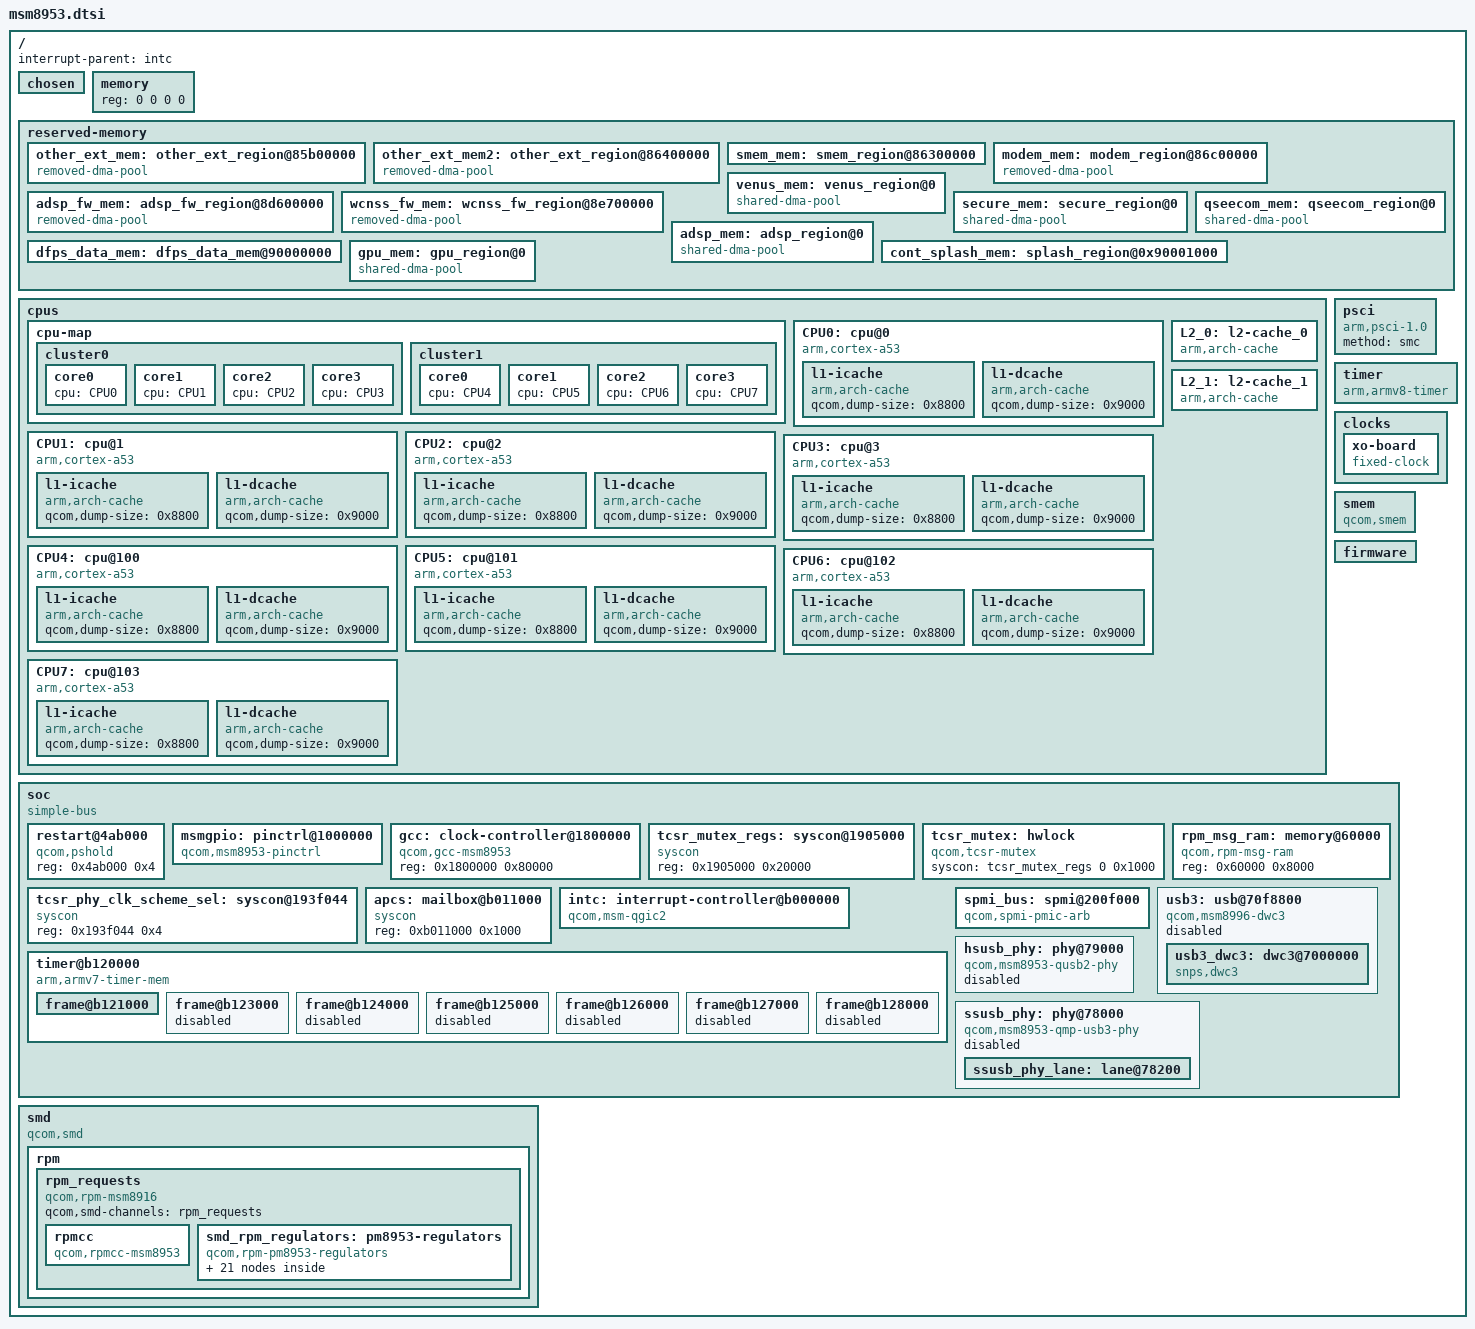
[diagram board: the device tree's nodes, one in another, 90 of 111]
// SPDX-License-Identifier: GPL-2.0-only
/* Copyright (c) 2020, The Linux Foundation. All rights reserved.
 */
#include <dt-bindings/interrupt-controller/arm-gic.h>
#include <dt-bindings/clock/qcom,gcc-msm8953.h>
#include <dt-bindings/clock/qcom,rpmcc.h>

/ {
	interrupt-parent = <&intc>;
	#address-cells = <2>;
	#size-cells = <2>;

	chosen { };

	memory {
		device_type = "memory";
		/* We expect the bootloader to fill in the reg */
		reg = <0 0 0 0>;
	};

	reserved-memory {
		#address-cells = <2>;
		#size-cells = <2>;
		ranges;

		other_ext_mem: other_ext_region@85b00000 {
			compatible = "removed-dma-pool";
			no-map;
			reg = <0x0 0x85b00000 0x0 0x800000>;
		};

		other_ext_mem2: other_ext_region@86400000 {
			compatible = "removed-dma-pool";
			no-map;
			reg = <0x0 0x86400000 0x0 0x400000>;
		};

		smem_mem: smem_region@86300000 {
			reg = <0x0 0x86300000 0x0 0x100000>;
			no-map;
		};

		modem_mem: modem_region@86c00000 {
			compatible = "removed-dma-pool";
			no-map-fixup;
			reg = <0x0 0x86c00000 0x0 0x6a00000>;
		};

		adsp_fw_mem: adsp_fw_region@8d600000 {
			compatible = "removed-dma-pool";
			no-map;
			reg = <0x0 0x8d600000 0x0 0x1100000>;
		};

		wcnss_fw_mem: wcnss_fw_region@8e700000 {
			compatible = "removed-dma-pool";
			no-map;
			reg = <0x0 0x8e700000 0x0 0x700000>;
		};

		venus_mem: venus_region@0 {
			compatible = "shared-dma-pool";
			reusable;
			alloc-ranges = <0x0 0x80000000 0x0 0x10000000>;
			alignment = <0 0x400000>;
			size = <0 0x0800000>;
		};

		secure_mem: secure_region@0 {
			compatible = "shared-dma-pool";
			reusable;
			alignment = <0 0x400000>;
			size = <0 0x09800000>;
		};

		qseecom_mem: qseecom_region@0 {
			compatible = "shared-dma-pool";
			reusable;
			alignment = <0 0x400000>;
			size = <0 0x1000000>;
		};

		adsp_mem: adsp_region@0 {
			compatible = "shared-dma-pool";
			reusable;
			size = <0 0x400000>;
		};

		dfps_data_mem: dfps_data_mem@90000000 {
			reg = <0 0x90000000 0 0x1000>;
			label = "dfps_data_mem";
		};

		cont_splash_mem: splash_region@0x90001000 {
			reg = <0x0 0x90001000 0x0 0x13ff000>;
			label = "cont_splash_mem";
		};

		gpu_mem: gpu_region@0 {
			compatible = "shared-dma-pool";
			reusable;
			alloc-ranges = <0x0 0x80000000 0x0 0x10000000>;
			alignment = <0 0x400000>;
			size = <0 0x800000>;
		};
	};

	cpus {
		#address-cells = <1>;
		#size-cells = <0>;

		cpu-map {
			cluster0 {
				core0 {
					cpu = <&CPU0>;
				};
				core1 {
					cpu = <&CPU1>;
				};
				core2 {
					cpu = <&CPU2>;
				};
				core3 {
					cpu = <&CPU3>;
				};
			};

			cluster1 {
				core0 {
					cpu = <&CPU4>;
				};
				core1 {
					cpu = <&CPU5>;
				};
				core2 {
					cpu = <&CPU6>;
				};
				core3 {
					cpu = <&CPU7>;
				};
			};
		};

		CPU0: cpu@0 {
			device_type = "cpu";
			compatible = "arm,cortex-a53";
			reg = <0x0>;
			enable-method = "psci";
			next-level-cache = <&L2_0>;

			l1-icache {
				compatible = "arm,arch-cache";
				qcom,dump-size = <0x8800>;
			};

			l1-dcache {
				compatible = "arm,arch-cache";
				qcom,dump-size = <0x9000>;
			};
		};

		CPU1: cpu@1 {
			device_type = "cpu";
			compatible = "arm,cortex-a53";
			enable-method = "psci";
			reg = <0x1>;
			next-level-cache = <&L2_0>;

			l1-icache {
				compatible = "arm,arch-cache";
				qcom,dump-size = <0x8800>;
			};

			l1-dcache {
				compatible = "arm,arch-cache";
				qcom,dump-size = <0x9000>;
			};
		};

		CPU2: cpu@2 {
			device_type = "cpu";
			compatible = "arm,cortex-a53";
			enable-method = "psci";
			reg = <0x2>;
			next-level-cache = <&L2_0>;

			l1-icache {
				compatible = "arm,arch-cache";
				qcom,dump-size = <0x8800>;
			};

			l1-dcache {
				compatible = "arm,arch-cache";
				qcom,dump-size = <0x9000>;
			};
		};

		CPU3: cpu@3 {
			device_type = "cpu";
			compatible = "arm,cortex-a53";
			enable-method = "psci";
			reg = <0x3>;
			next-level-cache = <&L2_0>;

			l1-icache {
				compatible = "arm,arch-cache";
				qcom,dump-size = <0x8800>;
			};

			l1-dcache {
				compatible = "arm,arch-cache";
				qcom,dump-size = <0x9000>;
			};
		};

		CPU4: cpu@100 {
			device_type = "cpu";
			compatible = "arm,cortex-a53";
			enable-method = "psci";
			reg = <0x100>;
			next-level-cache = <&L2_1>;

			l1-icache {
				compatible = "arm,arch-cache";
				qcom,dump-size = <0x8800>;
			};

			l1-dcache {
				compatible = "arm,arch-cache";
				qcom,dump-size = <0x9000>;
			};
		};

		CPU5: cpu@101 {
			device_type = "cpu";
			compatible = "arm,cortex-a53";
			enable-method = "psci";
			reg = <0x101>;
			next-level-cache = <&L2_1>;

			l1-icache {
				compatible = "arm,arch-cache";
				qcom,dump-size = <0x8800>;
			};

			l1-dcache {
				compatible = "arm,arch-cache";
				qcom,dump-size = <0x9000>;
			};
		};

		CPU6: cpu@102 {
			device_type = "cpu";
			compatible = "arm,cortex-a53";
			enable-method = "psci";
			reg = <0x102>;
			next-level-cache = <&L2_1>;

			l1-icache {
				compatible = "arm,arch-cache";
				qcom,dump-size = <0x8800>;
			};

			l1-dcache {
				compatible = "arm,arch-cache";
				qcom,dump-size = <0x9000>;
			};
		};

		CPU7: cpu@103 {
			device_type = "cpu";
			compatible = "arm,cortex-a53";
			enable-method = "psci";
			reg = <0x103>;
			next-level-cache = <&L2_1>;

			l1-icache {
				compatible = "arm,arch-cache";
				qcom,dump-size = <0x8800>;
			};

			l1-dcache {
				compatible = "arm,arch-cache";
				qcom,dump-size = <0x9000>;
			};
		};

		L2_0: l2-cache_0 {
			compatible = "arm,arch-cache";
			cache-level = <2>;
			qcom,dump-size = <0>;
		};

		L2_1: l2-cache_1 {
			compatible = "arm,arch-cache";
			cache-level = <2>;
			qcom,dump-size = <0>;
		};
	};

	psci {
		compatible = "arm,psci-1.0";
		method = "smc";
	};

	timer {
		compatible = "arm,armv8-timer";
		interrupts = <GIC_PPI 2 (GIC_CPU_MASK_SIMPLE(8) | IRQ_TYPE_LEVEL_LOW)>,
			     <GIC_PPI 3 (GIC_CPU_MASK_SIMPLE(8) | IRQ_TYPE_LEVEL_LOW)>,
			     <GIC_PPI 4 (GIC_CPU_MASK_SIMPLE(8) | IRQ_TYPE_LEVEL_LOW)>,
			     <GIC_PPI 1 (GIC_CPU_MASK_SIMPLE(8) | IRQ_TYPE_LEVEL_LOW)>;
		clock-frequency = <19200000>;
	};

	clocks {
		xo-board {
			compatible = "fixed-clock";
			#clock-cells = <0>;
			clock-frequency = <19200000>;
			clock-output-names = "xo_board";
		};
	};

	smem {
		compatible = "qcom,smem";

		memory-region = <&smem_mem>;
		qcom,rpm-msg-ram = <&rpm_msg_ram>;

		hwlocks = <&tcsr_mutex 3>;
	};

	firmware { };


	soc: soc {
		#address-cells = <1>;
		#size-cells = <1>;
		ranges = <0 0 0 0xffffffff>;
		compatible = "simple-bus";

		restart@4ab000 {
			compatible = "qcom,pshold";
			reg = <0x4ab000 0x4>;
		};

		msmgpio: pinctrl@1000000 {
			compatible = "qcom,msm8953-pinctrl";
			reg = <0x1000000 0x300000>;
			interrupts = <GIC_SPI 208 IRQ_TYPE_LEVEL_HIGH>;
			gpio-controller;
			#gpio-cells = <2>;
			interrupt-controller;
			#interrupt-cells = <2>;
		};

		gcc: clock-controller@1800000 {
			compatible = "qcom,gcc-msm8953";
			#clock-cells = <1>;
			#reset-cells = <1>;
			#power-domain-cells = <1>;
			reg = <0x1800000 0x80000>;
		};

		tcsr_mutex_regs: syscon@1905000 {
			compatible = "syscon";
			reg = <0x1905000 0x20000>;
		};

		tcsr_mutex: hwlock {
			compatible = "qcom,tcsr-mutex";
			syscon = <&tcsr_mutex_regs 0 0x1000>;
			#hwlock-cells = <1>;
		};

		tcsr_phy_clk_scheme_sel: syscon@193f044 {
			compatible = "syscon";
			reg = <0x193f044 0x4>;
		};

		rpm_msg_ram: memory@60000 {
			compatible = "qcom,rpm-msg-ram";
			reg = <0x60000 0x8000>;
		};
		apcs: mailbox@b011000 {
			compatible = "syscon";
			reg = <0xb011000 0x1000>;
			#mbox-cells = <1>;
		/*	clocks = <&a53pll>;
			#clock-cells = <0>; */
		};


		intc: interrupt-controller@b000000 {
			compatible = "qcom,msm-qgic2";
			interrupt-controller;
			#interrupt-cells = <3>;
			reg = <0x0b000000 0x1000>, <0x0b002000 0x1000>;
		};

		timer@b120000 {
			#address-cells = <0x01>;
			#size-cells = <0x01>;
			ranges;
			compatible = "arm,armv7-timer-mem";
			reg = <0xb120000 0x1000>;
			clock-frequency = <0x124f800>;

			frame@b121000 {
				frame-number = <0>;
				interrupts = <GIC_SPI 8 IRQ_TYPE_LEVEL_HIGH>,
							<GIC_SPI 7 IRQ_TYPE_LEVEL_HIGH>;
				reg = <0xb121000 0x1000 0xb122000 0x1000>;
			};

			frame@b123000 {
				frame-number = <1>;
				interrupts = <GIC_SPI 9 IRQ_TYPE_LEVEL_HIGH>;
				reg = <0xb123000 0x1000>;
				status = "disabled";
			};

			frame@b124000 {
				frame-number = <2>;
				interrupts = <GIC_SPI 10 IRQ_TYPE_LEVEL_HIGH>;
				reg = <0xb124000 0x1000>;
				status = "disabled";
			};

			frame@b125000 {
				frame-number = <3>;
				interrupts = <GIC_SPI 11 IRQ_TYPE_LEVEL_HIGH>;
				reg = <0xb125000 0x1000>;
				status = "disabled";
			};

			frame@b126000 {
				frame-number = <4>;
				interrupts = <GIC_SPI 12 IRQ_TYPE_LEVEL_HIGH>;
				reg = <0xb126000 0x1000>;
				status = "disabled";
			};

			frame@b127000 {
				frame-number = <5>;
				interrupts = <GIC_SPI 13 IRQ_TYPE_LEVEL_HIGH>;
				reg = <0xb127000 0x1000>;
				status = "disabled";
			};

			frame@b128000 {
				frame-number = <6>;
				interrupts = <GIC_SPI 14 IRQ_TYPE_LEVEL_HIGH>;
				reg = <0xb128000 0x1000>;
				status = "disabled";
			};
		};

		spmi_bus: spmi@200f000 {
			compatible = "qcom,spmi-pmic-arb";
			reg = <0x200f000 0x1000>,
			      <0x2400000 0x800000>,
			      <0x2c00000 0x800000>,
			      <0x3800000 0x200000>,
			      <0x200a000 0x2100>;
			reg-names = "core", "chnls", "obsrvr", "intr", "cnfg";
			interrupt-names = "periph_irq";
			interrupts = <GIC_SPI 190 IRQ_TYPE_LEVEL_HIGH>;
			qcom,max-peripherals = <256>;
			qcom,max-periph-interrupts = <256>;
			qcom,ee = <0>;
			qcom,channel = <0>;
			#address-cells = <2>;
			#size-cells = <0>;
			interrupt-controller;
			#interrupt-cells = <4>;
		};

		usb3: usb@70f8800 {
			compatible = "qcom,msm8996-dwc3", "qcom,dwc3";
			reg = <0x070f8800 0x400>;
			#address-cells = <1>;
			#size-cells = <1>;
			ranges;

			interrupts = <GIC_SPI 136 IRQ_TYPE_LEVEL_HIGH>,
				     <GIC_SPI 220 IRQ_TYPE_LEVEL_HIGH>;
			interrupt-names = "hs_phy_irq", "ss_phy_irq";

			clocks = <&gcc GCC_PCNOC_USB3_AXI_CLK>,
				<&gcc GCC_USB30_MASTER_CLK>,
				<&gcc GCC_USB30_MOCK_UTMI_CLK>,
				<&gcc GCC_USB30_SLEEP_CLK>,
				<&gcc GCC_USB_PHY_CFG_AHB_CLK>;

			clock-names = "iface", "core", "mock_utmi",
				"sleep", "cfg_noc";

			assigned-clocks = <&gcc GCC_USB30_MOCK_UTMI_CLK>,
					  <&gcc GCC_USB30_MASTER_CLK>;

			assigned-clock-rates = <19200000>, <133330000>;

			power-domains = <&gcc USB30_GDSC>;
			status = "disabled";

			usb3_dwc3: dwc3@7000000 {
				compatible = "snps,dwc3";
				reg = <0x07000000 0xcc00>;
				interrupts = <GIC_SPI 140 IRQ_TYPE_LEVEL_HIGH>;
				phys = <&hsusb_phy>, <&ssusb_phy_lane>;
				phy-names = "usb2-phy", "usb3-phy";
				snps,dis-del-phy-power-chg-quirk;
				snps,dis_u2_susphy_quirk;
				snps,dis_u3_susphy_quirk;
				phy_mode = "utmi";
				snps,hird-threshold = /bits/ 8 <0x10>;
			};
		};

		hsusb_phy: phy@79000 {
			compatible = "qcom,msm8953-qusb2-phy";
			reg = <0x00079000 0x180>;
			#phy-cells = <0>;

			clocks = <&gcc GCC_USB_PHY_CFG_AHB_CLK>,
				<&gcc GCC_QUSB_REF_CLK>;
			clock-names = "cfg_ahb", "ref";

			qcom,tcsr-syscon = <&tcsr_phy_clk_scheme_sel>;

			phy-supply = <&pm8953_l3>;
			vdda-pll-supply = <&pm8953_l7>;
			vdda-phy-dpdm-supply = <&pm8953_l13>;

			resets = <&gcc GCC_QUSB2_PHY_BCR>;
			status = "disabled";
		};

		ssusb_phy: phy@78000 {
			compatible = "qcom,msm8953-qmp-usb3-phy";
			reg = <0x78000 0x1c4>;
			#clock-cells = <1>;
			#address-cells = <1>;
			#size-cells = <1>;
			ranges;

			clocks = <&gcc GCC_USB3_AUX_CLK>,
				<&gcc GCC_USB_PHY_CFG_AHB_CLK>,
				<&gcc GCC_USB_SS_REF_CLK>;
			clock-names = "aux", "cfg_ahb", "ref";

			assigned-clocks = <&gcc GCC_USB3_AUX_CLK>;
			assigned-clock-rates = <19200000>;

			vdda-phy-supply = <&pm8953_l3>;
			vdda-pll-supply = <&pm8953_l7>;

			resets = <&gcc GCC_USB3_PHY_BCR>,
				<&gcc GCC_USB3PHY_PHY_BCR>;
			reset-names = "phy", "common";
			status = "disabled";

			ssusb_phy_lane: lane@78200 {
				reg = <0x78200 0x200>,
					<0x78400 0x130>,
					<0x78800 0x1e0>;
				#phy-cells = <0>;

				clock-output-names = "usb3_pipe_clk_src";
				clocks = <&gcc GCC_USB3_PIPE_CLK>;
				clock-names = "pipe0";
			};
		};
	};

	smd {
		compatible = "qcom,smd";

		rpm {
			interrupts = <GIC_SPI 168 IRQ_TYPE_EDGE_RISING>;
			qcom,ipc = <&apcs 8 0>;
			qcom,smd-edge = <15>;

			rpm_requests {
				compatible = "qcom,rpm-msm8916";
				qcom,smd-channels = "rpm_requests";

				rpmcc: rpmcc {
					compatible = "qcom,rpmcc-msm8953";
					#clock-cells = <1>;
				};

				smd_rpm_regulators: pm8953-regulators {
					compatible = "qcom,rpm-pm8953-regulators";

					pm8953_s1: s1 {};
					pm8953_s3: s3 {};
					pm8953_s4: s4 {};

					pm8953_l1: l1 {};
					pm8953_l2: l2 {};
					pm8953_l3: l3 {};
					pm8953_l5: l5 {};
					pm8953_l6: l6 {};
					pm8953_l7: l7 {};
					pm8953_l8: l8 {};
					pm8953_l9: l9 {};
					pm8953_l10: l10 {};
					pm8953_l11: l11 {};
					pm8953_l12: l12 {};
					pm8953_l13: l13 {};
					pm8953_l15: l15 {};
					pm8953_l16: l16 {};
					pm8953_l17: l17 {};
					pm8953_l19: l19 {};
					pm8953_l22: l22 {};
					pm8953_l23: l23 {};
				};
			};
		};
	};
};

#include "msm8953-pins.dtsi"
